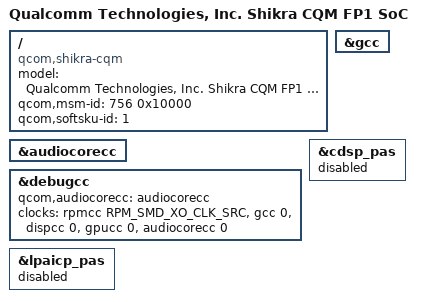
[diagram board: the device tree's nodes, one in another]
// SPDX-License-Identifier: BSD-3-Clause
/*
 * Copyright (c) Qualcomm Technologies, Inc. and/or its subsidiaries.
 */

#include "shikra-cqm.dtsi"
#include "shikra-lite-thermal.dtsi"
#include "shikra-pmic-overlay-pm4125.dtsi"

/ {
	model = "Qualcomm Technologies, Inc. Shikra CQM FP1 SoC";
	compatible = "qcom,shikra-cqm", "qcom,shikra";
	qcom,msm-id = <756 0x10000>;
	qcom,softsku-id = <1>;
};

&audiocorecc {
	status = "okay";
};

&gcc {
	/delete-property/ protected-clocks;
};

&debugcc {
	qcom,audiocorecc = <&audiocorecc>;
	clocks = <&rpmcc RPM_SMD_XO_CLK_SRC>,
		 <&gcc 0>,
		 <&dispcc 0>,
		 <&gpucc 0>,
		 <&audiocorecc 0>;
	clock-names = "xo_clk_src",
		      "gcc",
		      "dispcc",
		      "gpucc",
		      "audiocorecc";
};

&cdsp_pas {
	status = "disabled";
};

&lpaicp_pas {
	status = "disabled";
};
